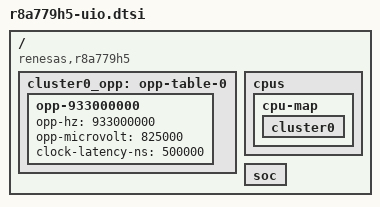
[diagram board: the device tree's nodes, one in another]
// SPDX-License-Identifier: (GPL-2.0-only OR BSD-2-Clause)
/*
 * UIO Device Tree Source for the R-Car V4M-2 (R8A779H5) SoC
 *
 * Copyright (C) 2024 Renesas Electronics Corp.
 */

#include "r8a779h0-uio.dtsi"

/ {
	compatible = "renesas,r8a779h5", "renesas,r8a779h0";

	cluster0_opp: opp-table-0 {
		opp-933000000 {
			opp-hz = /bits/ 64 <933000000>;
			opp-microvolt = <825000>;
			clock-latency-ns = <500000>;
		};
		/delete-node/opp-1000000000;
	};

	cpus {
		cpu-map {
			cluster0 {
				/delete-node/core3;
			};
		};

		/delete-node/cpu@300;
	};

	soc {
		/delete-node/gsx@fd000000;
		/delete-node/ethernet@e6820000;
	};
};
